# M3351 register map
File version: 1.0
Registers are 32-bit, read-write, reset 0x0 unless marked. A register's access mark holds for its fields unless they carry their own. Offsets are from the block's base; [hi:lo] are bit positions; {n}, {i} and the like mark numbered series; 'fields as' and 'values as' point back to an identical list.

## UUART0 — USCIUART Register Map
Base 0x400D0000
Same registers: UUART1 0x400D1000, UUART0_NS 0x500D0000, UUART1_NS 0x500D1000
0x00 UUART_CTL — USCI Control Register
  [2:0] FUNMODE — Function Mode. This bit field selects the protocol for this USCI controller. Selecting a protocol that is not available or a reserved combination disables the USCI. When switching between two protocols, the USCI has to be disabled before selecting a new protocol. Simultaneously, the USCI will be reset when user write 000 to FUNMODE.
    0=The USCI is disabled. All protocol related state machines are set to idle state; 1=The SPI protocol is selected; 2=The UART protocol is selected; 4=The I2C protocol is selected
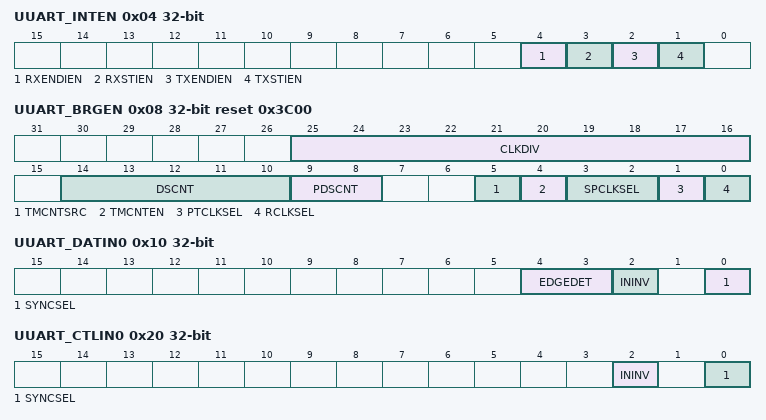
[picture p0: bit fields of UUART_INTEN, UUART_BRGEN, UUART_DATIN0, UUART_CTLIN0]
0x04 UUART_INTEN — USCI Interrupt Enable Register
  [4] RXENDIEN — Receive End Interrupt Enable Bit. This bit enables the interrupt generation in case of a receive finish event.
    0=The receive end interrupt Disabled; 1=The receive end interrupt Enabled
  [3] RXSTIEN — Receive Start Interrupt Enable Bit. This bit enables the interrupt generation in case of a receive start event.
    0=The receive start interrupt Disabled; 1=The receive start interrupt Enabled
  [2] TXENDIEN — Transmit End Interrupt Enable Bit. This bit enables the interrupt generation in case of a transmit finish event.
    0=The transmit finish interrupt Disabled; 1=The transmit finish interrupt Enabled
  [1] TXSTIEN — Transmit Start Interrupt Enable Bit. This bit enables the interrupt generation in case of a transmit start event.
    0=The transmit start interrupt Disabled; 1=The transmit start interrupt Enabled
0x08 UUART_BRGEN reset 0x3C00 — USCI Baud Rate Generator Register
  [25:16] CLKDIV — Clock Divider. Note: In UART function, it can be updated by hardware in the 4th falling edge of the input data 0x55 when the auto baud rate function (ABREN(UUART_PROTCTL[6])) is enabled. The revised value is the average bit time between bit 5 and bit 6. The user can use revised CLKDIV and new BRDETITV (UUART_PROTCTL[24:16]) to calculate the precise baud rate.
  [14:10] DSCNT — Denominator for Sample Counter. This bit field defines the divide ratio of the sample clock fSAMP_CLK. Note: The maximum value of DSCNT is 0xF on UART mode and suggest to set over 4 to confirm the receiver data is sampled in right value.
  [9:8] PDSCNT — Pre-divider for Sample Counter
  [5] TMCNTSRC — Timing Measurement Counter Clock Source Selection
    0=Timing measurement counter with fPROT_CLK; 1=Timing measurement counter with fDIV_CLK
  [4] TMCNTEN — Timing Measurement Counter Enable Bit. This bit enables the 10-bit timing measurement counter.
    0=Timing measurement counter is Disabled; 1=Timing measurement counter is Enabled
  [3:2] SPCLKSEL — Sample Clock Source Selection. This bit field used for the clock source selection of a sample clock (fSAMP_CLK) for the protocol processor.
    0=fSAMP_CLK is selected to fDIV_CLK; 1=fSAMP_CLK is selected to fPROT_CLK; 2=fSAMP_CLK is selected to fSCLK; 3=fSAMP_CLK is selected to fREF_CLK
  [1] PTCLKSEL — Protocol Clock Source Selection. This bit selects the source signal of protocol clock (fPROT_CLK).
    0=Reference clock fREF_CLK; 1=fREF_CLK2 (its frequency is half of fREF_CLK)
  [0] RCLKSEL — Reference Clock Source Selection. This bit selects the source signal of reference clock (fREF_CLK).
    0=Peripheral device clock fPCLK
0x10 UUART_DATIN0 — USCI Input Data Signal Configuration Register 0
  [4:3] EDGEDET — Input Signal Edge Detection Mode. This bit field selects which edge actives the trigger event of input data signal. Note: In UART function mode, it is suggested to set this bit field as 0x2.
    0=The trigger event activation is disabled; 1=A rising edge activates the trigger event of input data signal; 2=A falling edge activates the trigger event of input data signal; 3=Both edges activate the trigger event of input data signal
  [2] ININV — Input Signal Inverse Selection. This bit defines the inverter enable of the input asynchronous signal.
    0=The un-synchronized input signal will not be inverted; 1=The un-synchronized input signal will be inverted
  [0] SYNCSEL — Input Signal Synchronization Selection. This bit selects if the un-synchronized input signal (with optionally inverted) or the synchronized (and optionally filtered) signal can be used as input for the data shift unit.
    0=The un-synchronized signal can be taken as input for the data shift unit; 1=The synchronized signal can be taken as input for the data shift unit
0x20 UUART_CTLIN0 — USCI Input Control Signal Configuration Register 0
  [2] ININV — Input Signal Inverse Selection. This bit defines the inverter enable of the input asynchronous signal.
    values as UUART_DATIN0.ININV
  [0] SYNCSEL — Input Synchronization Signal Selection. This bit selects if the un-synchronized input signal (with optionally inverted) or the synchronized (and optionally filtered) signal can be used as input for the data shift unit.
    values as UUART_DATIN0.SYNCSEL
0x28 UUART_CLKIN — USCI Input Clock Signal Configuration Register
  [0] SYNCSEL — Input Synchronization Signal Selection. This bit selects if the un-synchronized input signal or the synchronized (and optionally filtered) signal can be used as input for the data shift unit.
    values as UUART_DATIN0.SYNCSEL
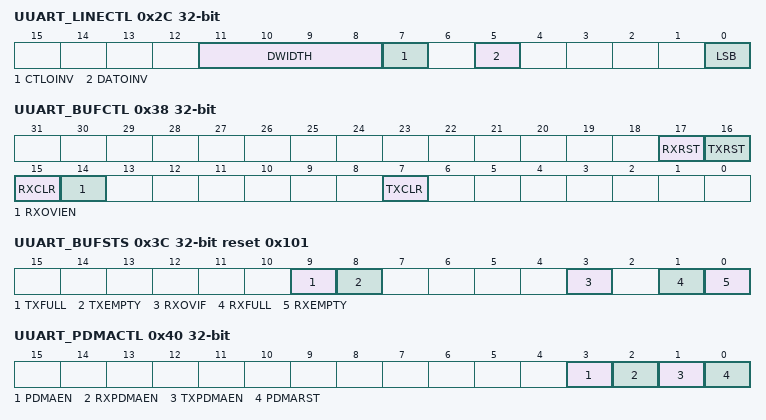
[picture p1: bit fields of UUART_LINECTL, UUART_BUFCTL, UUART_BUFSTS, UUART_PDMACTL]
0x2C UUART_LINECTL — USCI Line Control Register
  [11:8] DWIDTH — Word Length of Transmission. This bit field defines the data word length (amount of bits) for reception and transmission. The data word is always right-aligned in the data buffer. USCI support word length from 4 to 16 bits. Note: In UART protocol, the length can be configured as 6~13 bits.
    0=The data word contains 16 bits located at bit positions [15:0]; {v}=The data word contains {v} bits located at bit positions [{v-1}:0] (v=4..15)
  [7] CTLOINV — Control Signal Output Inverse Selection. This bit defines the relation between the internal control signal and the output control signal. Note: In UART protocol, the control signal means nRTS signal.
    0=No effect; 1=The control signal will be inverted before its output
  [5] DATOINV — Data Output Inverse Selection. This bit defines the relation between the internal shift data value and the output data signal of USCIx_DAT1 pin.
    0=The value of USCIx_DAT1 is equal to the data shift register; 1=The value of USCIx_DAT1 is the inversion of data shift register
  [0] LSB — LSB First Transmission Selection
    0=The MSB, which bit of transmit/receive data buffer depends on the setting of DWIDTH, is transmitted/received first; 1=The LSB, the bit 0 of data buffer, will be transmitted/received first
0x30 UUART_TXDAT wo — USCI Transmit Data Register
  [15:0] TXDAT — Transmit Data. Software can use this bit field to write 16-bit transmit data for transmission.
0x34 UUART_RXDAT ro — USCI Receive Data Register
  [15:0] RXDAT — Received Data. This bit field monitors the received data which stored in receive data buffer. Note: RXDAT[15:13] indicate the same frame status of BREAK, FRMERR and PARITYERR (UUART_PROTSTS[7:5]).
0x38 UUART_BUFCTL — USCI Transmit/Receive Buffer Control Register
  [17] RXRST — Receive Reset. Note 1: It is cleared automatically after one PCLK cycle. Note 2: It is suggested to check the RXBUSY (UUART_PROTSTS[10]) before this bit will be set to 1.
    0=No effect; 1=Reset the receive-related counters, state machine, and the content of receive shift register and data buffer
  [16] TXRST — Transmit Reset. Note: It is cleared automatically after one PCLK cycle.
    0=No effect; 1=Reset the transmit-related counters, state machine, and the content of transmit shift register and data buffer
  [15] RXCLR — Clear Receive Buffer. Note: It is cleared automatically after one PCLK cycle.
    0=No effect; 1=The receive buffer is cleared (filling level is cleared and output pointer is set to input pointer value). Should only be used while the buffer is not taking part in data traffic
  [14] RXOVIEN — Receive Buffer Overrun Error Interrupt Enable Bit
    0=Receive overrun interrupt Disabled; 1=Receive overrun interrupt Enabled
  [7] TXCLR — Clear Transmit Buffer. Note: It is cleared automatically after one PCLK cycle.
    0=No effect; 1=The transmit buffer is cleared (filling level is cleared and output pointer is set to input pointer value). Should only be used while the buffer is not taking part in data traffic
0x3C UUART_BUFSTS reset 0x101 — USCI Transmit/Receive Buffer Status Register
  [9] TXFULL — Transmit Buffer Full Indicator. Note: This bit is read only.
    0=Transmit buffer is not full; 1=Transmit buffer is full
  [8] TXEMPTY — Transmit Buffer Empty Indicator. Note: This bit is read only.
    0=Transmit buffer is not empty; 1=Transmit buffer is empty
  [3] RXOVIF — Receive Buffer Over-run Error Interrupt Status. This bit indicates that a receive buffer overrun error event has been detected. If RXOVIEN (UUART_BUFCTL[14]) is enabled, the corresponding interrupt request is activated. It is cleared by software writes 1 to this bit.
    0=A receive buffer overrun error event has not been detected; 1=A receive buffer overrun error event has been detected
  [1] RXFULL — Receive Buffer Full Indicator. Note: This bit is read only.
    0=Receive buffer is not full; 1=Receive buffer is full
  [0] RXEMPTY — Receive Buffer Empty Indicator. Note: This bit is read only.
    0=Receive buffer is not empty; 1=Receive buffer is empty
0x40 UUART_PDMACTL — USCI PDMA Control Register
  [3] PDMAEN — PDMA Mode Enable Bit
    0=PDMA function Disabled; 1=PDMA function Enabled
  [2] RXPDMAEN — PDMA Receive Channel Available
    0=Receive PDMA function Disabled; 1=Receive PDMA function Enabled
  [1] TXPDMAEN — PDMA Transmit Channel Available
    0=Transmit PDMA function Disabled; 1=Transmit PDMA function Enabled
  [0] PDMARST — PDMA Reset
    0=No effect; 1=Reset the USCI's PDMA control logic. This bit will be cleared to 0 automatically
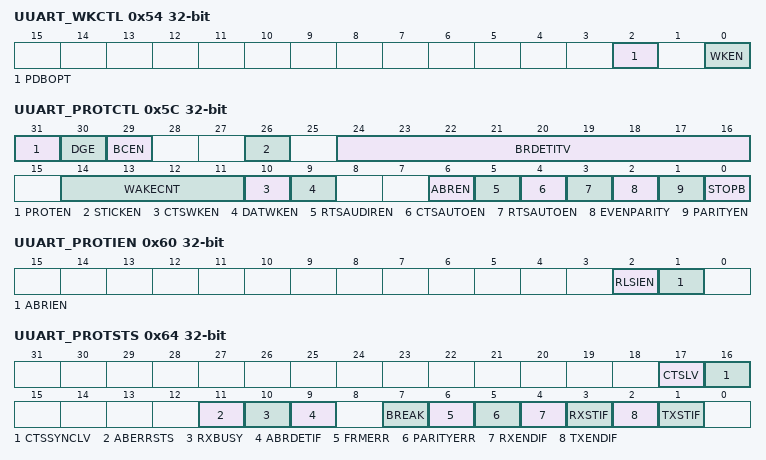
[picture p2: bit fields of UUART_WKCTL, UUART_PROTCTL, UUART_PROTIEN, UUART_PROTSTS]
0x54 UUART_WKCTL — USCI Wake-up Control Register
  [2] PDBOPT — Power Down Blocking Option
    0=If user attempts to enter Power-down mode by executing WFI while the protocol is in transferring, MCU will stop the transfer and enter Power-down mode immediately; 1=If user attempts to enter Power-down mode by executing WFI while the protocol is in transferring, the on-going transfer will not be stopped and MCU will enter idle mode immediately
  [0] WKEN — Wake-up Enable Bit
    0=Wake-up function Disabled; 1=Wake-up function Enabled
0x58 UUART_WKSTS — USCI Wake-up Status Register
  [0] WKF — Wake-up Flag. When chip is woken up from Power-down mode, this bit is set to 1. Software can write 1 to clear this bit.
0x5C UUART_PROTCTL — USCI Protocol Control Register
  [31] PROTEN — UART Protocol Enable Bit
    0=UART Protocol Disabled; 1=UART Protocol Enabled
  [30] DGE — Deglitch Enable Bit. Note 1: When this bit is set to logic 1, any pulse width less than about 150 ns will be considered a glitch and will be removed in the serial data input (RX). This bit acts only on RX line and has no effect on the transmitter logic. Note 2: It is recommended to set this bit only when operating at baud rate under 2.5 Mbps.
    0=Deglitch Disabled; 1=Deglitch Enabled
  [29] BCEN — Transmit Break Control Enable Bit. Note: When this bit is set to logic 1, the serial data output (TX) is forced to the Spacing State (logic 0). This bit acts only on TX line and has no effect on the transmitter logic.
    0=Transmit Break Control Disabled; 1=Transmit Break Control Enabled
  [26] STICKEN — Stick Parity Enable Bit. Note: Refer to RS-485 Support section for detailed information.
    0=Stick parity Disabled; 1=Stick parity Enabled
  [24:16] BRDETITV — Baud Rate Detection Interval. This bit fields indicate how many clock cycle selected by TMCNTSRC (UUART_BRGEN [5]) does the slave calculates the baud rate in one bits. The order of the bus shall be 1 and 0 step by step (e.g. the input data pattern shall be 0x55). The user can read the value to know the current input baud rate of the bus whenever the ABRDETIF (UUART_PROTSTS[9]) is set. Note: This bit can be cleared to 0 by software writing '0' to the BRDETITV.
  [14:11] WAKECNT — Wake-up Counter. These bits field indicate how many clock cycle selected by fPDS_CNT do the slave can get the 1st bit (START bit) when the device is wake-up from Power-down mode.
  [10] CTSWKEN — nCTS Wake-up Mode Enable Bit
    0=nCTS wake-up mode Disabled; 1=nCTS wake-up mode Enabled
  [9] DATWKEN — Data Wake-up Mode Enable Bit
    0=Data wake-up mode Disabled; 1=Data wake-up mode Enabled
  [6] ABREN — Auto-baud Rate Detect Enable Bit. Note: When the auto - baud rate detect operation finishes, hardware will clear this bit. The associated interrupt ABRDETIF (UUART_PROTSTS[9]) will be generated (If ABRIEN (UUART_PROTIEN [1]) is enabled).
    0=Auto-baud rate detect function Disabled; 1=Auto-baud rate detect function Enabled
  [5] RTSAUDIREN — nRTS Auto Direction Enable Bit. When nRTS auto direction is enabled, if the transmitted bytes in the TX buffer is empty, the UART asserted nRTS signal automatically. Note 1: This bit is used for nRTS auto direction control for RS485. Note 2: This bit has effect only when the RTSAUTOEN is not set.
    0=nRTS auto direction control Disabled; 1=nRTS auto direction control Enabled
  [4] CTSAUTOEN — nCTS Auto-flow Control Enable Bit. When nCTS auto-flow is enabled, the UART will send data to external device when nCTS input assert (UART will not send data to device if nCTS input is dis-asserted).
    0=nCTS auto-flow control Disabled; 1=nCTS auto-flow control Enabled
  [3] RTSAUTOEN — nRTS Auto-flow Control Enable Bit. Note: This bit has effect only when the RTSAUDIREN is not set.
    0=nRTS auto-flow control Disabled; 1=nRTS auto-flow control Enabled
  [2] EVENPARITY — Even Parity Enable Bit. Note: This bit has effect only when PARITYEN is set.
    0=Odd number of logic 1's is transmitted and checked in each word; 1=Even number of logic 1's is transmitted and checked in each word
  [1] PARITYEN — Parity Enable Bit. This bit defines the PARITY bit is enabled in an UART frame.
    0=The PARITY bit Disabled; 1=The PARITY bit Enabled
  [0] STOPB — STOP bits. This bit defines the number of STOP bits in an UART frame.
    0=The number of STOP bits is 1; 1=The number of STOP bits is 2
0x60 UUART_PROTIEN — USCI Protocol Interrupt Enable Register
  [2] RLSIEN — Receive Line Status Interrupt Enable Bit. Note: UUART_PROTSTS[7:5] indicates the current interrupt event for receive line status interrupt.
    0=Receive line status interrupt Disabled; 1=Receive line status interrupt Enabled
  [1] ABRIEN — Auto-baud Rate Interrupt Enable Bit
    0=Auto-baud rate interrupt Disabled; 1=Auto-baud rate interrupt Enabled
0x64 UUART_PROTSTS — USCI Protocol Status Register
  [17] CTSLV — nCTS Pin Status (Read Only). This bit used to monitor the current status of nCTS pin input.
    0=nCTS pin input is low level voltage logic state; 1=nCTS pin input is high level voltage logic state
  [16] CTSSYNCLV — nCTS Synchronized Level Status (Read Only). This bit used to indicate the current status of the internal synchronized nCTS signal.
    0=The internal synchronized nCTS is low; 1=The internal synchronized nCTS is high
  [11] ABERRSTS — Auto-baud Rate Error Status. This bit is set when auto-baud rate detection counter overrun. When the auto-baud rate counter overrun, the user shall revise the CLKDIV (UUART_BRGEN[25:16]) value and enable ABREN (UUART_PROTCTL[6]) to detect the correct baud rate again. Note 1: This bit is set at the same time of ABRDETIF. Note 2: This bit can be cleared by writing '1' to ABRDETIF or ABERRSTS.
    0=Auto-baud rate detect counter is not overrun; 1=Auto-baud rate detect counter is overrun
  [10] RXBUSY — RX Bus Status Flag (Read Only). This bit indicates the busy status of the receiver.
    0=The receiver is Idle; 1=The receiver is BUSY
  [9] ABRDETIF — Auto-baud Rate Interrupt Flag. This bit is set when auto-baud rate detection is done among the falling edge of the input data. If the ABRIEN (UUART_PROTIEN[1]) is set, the auto-baud rate interrupt will be generated. This bit can be set 4 times when the input data pattern is 0x55 and it is cleared before the next falling edge of the input bus. Note: This bit can be cleared by writing '1' to it.
    0=Auto-baud rate detect function is not done; 1=One Bit auto-baud rate detect function is done
  [7] BREAK — Break Flag. This bit is set to logic 1 whenever the received data input (RX) is held in the 'spacing state' (logic 0) for longer than a full word transmission time (that is, the total time of 'START bit' + data bits + parity + STOP bits). Note: This bit can be cleared by writing '1' among the BREAK, FRMERR and PARITYERR bits.
    0=No Break is generated; 1=Break is generated in the receiver bus
  [6] FRMERR — Framing Error Flag. This bit is set to logic 1 whenever the received character does not have a valid 'STOP bit' (that is, the STOP bit following the last data bit or PARITY bit is detected as logic 0). Note: This bit can be cleared by writing '1' among the BREAK, FRMERR and PARITYERR bits.
    0=No framing error is generated; 1=Framing error is generated
  [5] PARITYERR — Parity Error Flag. This bit is set to logic 1 whenever the received character does not have a valid 'PARITY bit'. Note: This bit can be cleared by writing '1' among the BREAK, FRMERR and PARITYERR bits.
    0=No parity error is generated; 1=Parity error is generated
  [4] RXENDIF — Receive End Interrupt Flag. Note: It is cleared by software writing 1 into this bit.
    0=A receive finish interrupt status has not occurred; 1=A receive finish interrupt status has occurred
  [3] RXSTIF — Receive Start Interrupt Flag. Note: It is cleared by software writing 1 into this bit.
    0=A receive start interrupt status has not occurred; 1=A receive start interrupt status has occurred
  [2] TXENDIF — Transmit End Interrupt Flag. Note: It is cleared by software writing 1 into this bit.
    0=A transmit end interrupt status has not occurred; 1=A transmit end interrupt status has occurred
  [1] TXSTIF — Transmit Start Interrupt Flag. Note 1: It is cleared by software writing 1 into this bit. Note 2: Used for user to load next transmit data when there is no data in transmit buffer.
    0=A transmit start interrupt status has not occurred; 1=A transmit start interrupt status has occurred
